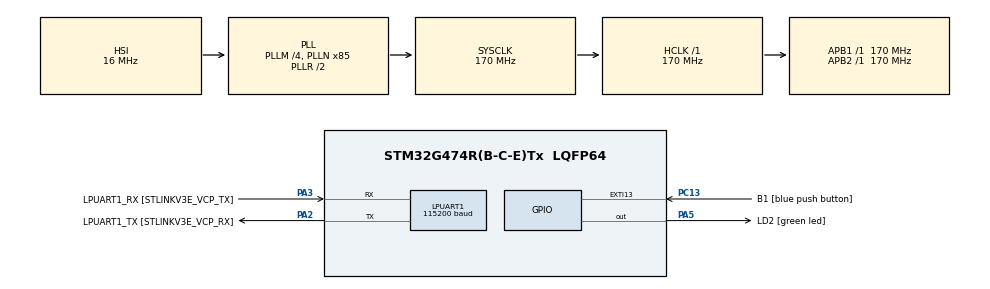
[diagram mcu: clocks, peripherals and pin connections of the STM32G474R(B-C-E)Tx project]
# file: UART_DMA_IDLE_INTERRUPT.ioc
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Dma.LPUART1_RX.0.Direction=DMA_PERIPH_TO_MEMORY
Dma.LPUART1_RX.0.EventEnable=DISABLE
Dma.LPUART1_RX.0.Instance=DMA1_Channel1
Dma.LPUART1_RX.0.MemDataAlignment=DMA_MDATAALIGN_BYTE
Dma.LPUART1_RX.0.MemInc=DMA_MINC_ENABLE
Dma.LPUART1_RX.0.Mode=DMA_NORMAL
Dma.LPUART1_RX.0.PeriphDataAlignment=DMA_PDATAALIGN_BYTE
Dma.LPUART1_RX.0.PeriphInc=DMA_PINC_DISABLE
Dma.LPUART1_RX.0.Polarity=HAL_DMAMUX_REQ_GEN_RISING
Dma.LPUART1_RX.0.Priority=DMA_PRIORITY_LOW
Dma.LPUART1_RX.0.RequestNumber=1
Dma.LPUART1_RX.0.SignalID=NONE
Dma.LPUART1_RX.0.SyncEnable=DISABLE
Dma.LPUART1_RX.0.SyncPolarity=HAL_DMAMUX_SYNC_NO_EVENT
Dma.LPUART1_RX.0.SyncRequestNumber=1
Dma.LPUART1_RX.0.SyncSignalID=NONE
Dma.LPUART1_TX.1.Direction=DMA_MEMORY_TO_PERIPH
Dma.LPUART1_TX.1.EventEnable=DISABLE
Dma.LPUART1_TX.1.Instance=DMA1_Channel2
Dma.LPUART1_TX.1.MemDataAlignment=DMA_MDATAALIGN_BYTE
Dma.LPUART1_TX.1.MemInc=DMA_MINC_ENABLE
Dma.LPUART1_TX.1.Mode=DMA_NORMAL
Dma.LPUART1_TX.1.PeriphDataAlignment=DMA_PDATAALIGN_BYTE
Dma.LPUART1_TX.1.PeriphInc=DMA_PINC_DISABLE
Dma.LPUART1_TX.1.Polarity=HAL_DMAMUX_REQ_GEN_RISING
Dma.LPUART1_TX.1.Priority=DMA_PRIORITY_LOW
Dma.LPUART1_TX.1.RequestNumber=1
Dma.LPUART1_TX.1.SignalID=NONE
Dma.LPUART1_TX.1.SyncEnable=DISABLE
Dma.LPUART1_TX.1.SyncPolarity=HAL_DMAMUX_SYNC_NO_EVENT
Dma.LPUART1_TX.1.SyncRequestNumber=1
Dma.LPUART1_TX.1.SyncSignalID=NONE
Dma.Request0=LPUART1_RX
Dma.Request1=LPUART1_TX
LPUART1.BaudRate=115200
LPUART1.WordLength=UART_WORDLENGTH_8B
Mcu.Family=STM32G4
Mcu.Name=STM32G474R(B-C-E)Tx
Mcu.Package=LQFP64
NVIC.DMA1_Channel1_IRQn=true\:0\:0\:true\:false\:true\:false\:true
NVIC.DMA1_Channel2_IRQn=true\:0\:0\:true\:false\:true\:false\:true
NVIC.EXTI15_10_IRQn=true\:0\:0\:false\:false\:true\:true\:true
NVIC.LPUART1_IRQn=true\:0\:0\:true\:false\:true\:true\:true
NVIC.PriorityGroup=NVIC_PRIORITYGROUP_4
PA13.GPIO_Label=T_SWDIO
PA13.Mode=Serial_Wire
PA13.Signal=SYS_JTMS-SWDIO
PA14.GPIO_Label=T_SWCLK
PA14.Mode=Serial_Wire
PA14.Signal=SYS_JTCK-SWCLK
PA2.GPIO_Label=LPUART1_TX [STLINKV3E_VCP_RX]
PA2.Mode=Asynchronous
PA2.Signal=LPUART1_TX
PA3.GPIO_Label=LPUART1_RX [STLINKV3E_VCP_TX]
PA3.Mode=Asynchronous
PA3.Signal=LPUART1_RX
PA5.GPIO_Label=LD2 [green led]
PA5.Signal=GPIO_Output
PB3.GPIO_Label=T_SWO
PB3.Signal=SYS_JTDO-SWO
PC13.GPIO_Label=B1 [blue push button]
PC13.Signal=GPXTI13
PC14-OSC32_IN.Mode=LSE-External-Oscillator
PC14-OSC32_IN.Signal=RCC_OSC32_IN
PC15-OSC32_OUT.Mode=LSE-External-Oscillator
PC15-OSC32_OUT.Signal=RCC_OSC32_OUT
PF0-OSC_IN.Mode=HSE-External-Oscillator
PF0-OSC_IN.Signal=RCC_OSC_IN
PF1-OSC_OUT.Mode=HSE-External-Oscillator
PF1-OSC_OUT.Signal=RCC_OSC_OUT
ProjectManager.HeapSize=0x200
ProjectManager.StackSize=0x400
ProjectManager.TargetToolchain=STM32CubeIDE
RCC.ADC12Freq_Value=170000000
RCC.ADC345Freq_Value=170000000
RCC.AHBFreq_Value=170000000
RCC.APB1Freq_Value=170000000
RCC.APB1TimFreq_Value=170000000
RCC.APB2Freq_Value=170000000
RCC.APB2TimFreq_Value=170000000
RCC.CortexFreq_Value=170000000
RCC.EXTERNAL_CLOCK_VALUE=12288000
RCC.HCLKFreq_Value=170000000
RCC.HSE_VALUE=24000000
RCC.HSI48_VALUE=48000000
RCC.HSI_VALUE=16000000
RCC.PLLM=RCC_PLLM_DIV4
RCC.PLLN=85
RCC.RTCClockSelection=RCC_RTCCLKSOURCE_LSE
RCC.SYSCLKFreq_VALUE=170000000
RCC.SYSCLKSource=RCC_SYSCLKSOURCE_PLLCLK
RCC.USBFreq_Value=170000000
RCC.VCOOutputFreq_Value=340000000
VP_SYS_VS_DBSignals.Mode=DisableDeadBatterySignals
board=NUCLEO-G474RE

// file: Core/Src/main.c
/* USER CODE BEGIN Header */
/**
  ******************************************************************************
  * @file           : main.c
  * @brief          : Main program body
  ******************************************************************************
  * @attention
  *
  * <h2><center>&copy; Copyright (c) 2021 STMicroelectronics.
  * All rights reserved.</center></h2>
  *
  * This software component is licensed by ST under BSD 3-Clause license,
  * the "License"; You may not use this file except in compliance with the
  * License. You may obtain a copy of the License at:
  *                        opensource.org/licenses/BSD-3-Clause
  *
  ******************************************************************************
  */
/* USER CODE END Header */
#include "main.h"
#include "dma.h"
#include "usart.h"
#include "gpio.h"

void SystemClock_Config(void);

/* USER CODE BEGIN 0 */
uint8_t BUFFERSIZE = 255;
uint8_t ReceiveBuff[255]; //缓冲区定�??
uint8_t Rx_len;                  //接收字符长度

/* USER CODE END 0 */

int main(void)
{

  /* MCU Configuration--------------------------------------------------------*/

  /* Reset of all peripherals, Initializes the Flash interface and the Systick. */
  HAL_Init();

  /* Configure the system clock */
  SystemClock_Config();

  /* Initialize all configured peripherals */
  MX_GPIO_Init();
  MX_DMA_Init();
  MX_LPUART1_UART_Init();
  /* USER CODE BEGIN 2 */

  __HAL_UART_ENABLE_IT(&hlpuart1, UART_IT_IDLE);          //�??串口空闲中断
  HAL_UART_Receive_DMA(&hlpuart1,ReceiveBuff,BUFFERSIZE); //�??串口接收DMA

  /* USER CODE END 2 */

  /* Infinite loop */
  while (1)
  {

  }
}

void SystemClock_Config(void)
{
  RCC_OscInitTypeDef RCC_OscInitStruct = {0};
  RCC_ClkInitTypeDef RCC_ClkInitStruct = {0};
  RCC_PeriphCLKInitTypeDef PeriphClkInit = {0};

  /** Configure the main internal regulator output voltage
  */
  HAL_PWREx_ControlVoltageScaling(PWR_REGULATOR_VOLTAGE_SCALE1_BOOST);
  /** Initializes the RCC Oscillators according to the specified parameters
  * in the RCC_OscInitTypeDef structure.
  */
  RCC_OscInitStruct.OscillatorType = RCC_OSCILLATORTYPE_HSI;
  RCC_OscInitStruct.HSIState = RCC_HSI_ON;
  RCC_OscInitStruct.HSICalibrationValue = RCC_HSICALIBRATION_DEFAULT;
  RCC_OscInitStruct.PLL.PLLState = RCC_PLL_ON;
  RCC_OscInitStruct.PLL.PLLSource = RCC_PLLSOURCE_HSI;
  RCC_OscInitStruct.PLL.PLLM = RCC_PLLM_DIV4;
  RCC_OscInitStruct.PLL.PLLN = 85;
  RCC_OscInitStruct.PLL.PLLP = RCC_PLLP_DIV2;
  RCC_OscInitStruct.PLL.PLLQ = RCC_PLLQ_DIV2;
  RCC_OscInitStruct.PLL.PLLR = RCC_PLLR_DIV2;
  if (HAL_RCC_OscConfig(&RCC_OscInitStruct) != HAL_OK)
  {
    Error_Handler();
  }
  /** Initializes the CPU, AHB and APB buses clocks
  */
  RCC_ClkInitStruct.ClockType = RCC_CLOCKTYPE_HCLK|RCC_CLOCKTYPE_SYSCLK
                              |RCC_CLOCKTYPE_PCLK1|RCC_CLOCKTYPE_PCLK2;
  RCC_ClkInitStruct.SYSCLKSource = RCC_SYSCLKSOURCE_PLLCLK;
  RCC_ClkInitStruct.AHBCLKDivider = RCC_SYSCLK_DIV1;
  RCC_ClkInitStruct.APB1CLKDivider = RCC_HCLK_DIV1;
  RCC_ClkInitStruct.APB2CLKDivider = RCC_HCLK_DIV1;

  if (HAL_RCC_ClockConfig(&RCC_ClkInitStruct, FLASH_LATENCY_4) != HAL_OK)
  {
    Error_Handler();
  }
  /** Initializes the peripherals clocks
  */
  PeriphClkInit.PeriphClockSelection = RCC_PERIPHCLK_LPUART1;
  PeriphClkInit.Lpuart1ClockSelection = RCC_LPUART1CLKSOURCE_PCLK1;
  if (HAL_RCCEx_PeriphCLKConfig(&PeriphClkInit) != HAL_OK)
  {
    Error_Handler();
  }
}

void Error_Handler(void)
{
  __disable_irq();
  while (1)
  {
  }
}

/************************ (C) COPYRIGHT STMicroelectronics *****END OF FILE****/
